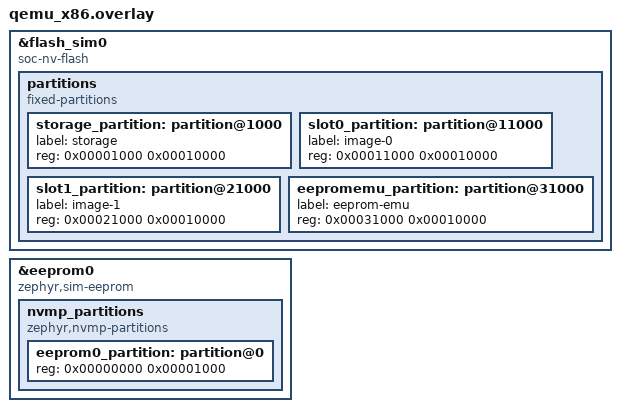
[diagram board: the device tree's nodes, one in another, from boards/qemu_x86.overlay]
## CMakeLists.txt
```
# Copyright (c) 2024 Laczen
# SPDX-License-Identifier: Apache-2.0

cmake_minimum_required(VERSION 3.20.0)

find_package(Zephyr REQUIRED HINTS $ENV{ZEPHYR_BASE})
project(nvmp_test)

target_sources(app PRIVATE src/main.c)
```

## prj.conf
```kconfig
# Copyright (c) 2024 Laczen
# SPDX-License-Identifier: Apache-2.0
CONFIG_NVMP=y
CONFIG_FLASH=y
CONFIG_EEPROM=y
CONFIG_USERSPACE=n
CONFIG_ZTEST=y
```

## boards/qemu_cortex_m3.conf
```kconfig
# Copyright (c) 2023 Laczen
# SPDX-License-Identifier: Apache-2.0
CONFIG_RETAINED_MEM=y
CONFIG_LOG=y
```

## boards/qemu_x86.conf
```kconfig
# Copyright (c) 2023 Laczen
# SPDX-License-Identifier: Apache-2.0
CONFIG_FLASH=y
CONFIG_NVMP_FLASH=y
CONFIG_EEPROM=y
CONFIG_NVMP_EEPROM=y
CONFIG_USERSPACE=n
```

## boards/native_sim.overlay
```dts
/*
 * Copyright (c) 2024 Laczen
 * SPDX-License-Identifier: Apache-2.0
 */

&flash0 {
        compatible = "soc-nv-flash";

	nvmp_partitions {
		compatible = "zephyr,flash-nvmp-fixed-partitions";
		#address-cells = <1>;
		#size-cells = <1>;

		flash0_partition0: partition@0 {
			reg = <0x00000000 0x00002000>;
                        block-size = <DT_SIZE_K(8)>;
		};

                flash0_partition1: partition@2000 {
			reg = <0x00002000 0x00002000>;
			write-block-size = <4>;
		};
	};
};

&eeprom0 {
        compatible = "zephyr,sim-eeprom";

	nvmp_partitions {
		compatible = "zephyr,eeprom-nvmp-fixed-partitions";
		#address-cells = <1>;
		#size-cells = <1>;

		eeprom0_partition0: partition@0 {
			reg = <0x00000000 0x00000800>;
                        block-size = <DT_SIZE_K(1)>;
			status = "okay";
		};

		eeprom0_partition1: partition@800 {
			reg = <0x00000800 0x00000800>;
			status = "okay";
		};

	};
};
```

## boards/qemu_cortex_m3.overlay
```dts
/*
 * Copyright (c) 2023 Laczen
 * SPDX-License-Identifier: Apache-2.0
 */

#include <common/mem.h>

/ {
	sram_2000FC00: sram@2000FC00 {
		compatible = "zephyr,memory-region", "mmio-sram";
		reg = <0x2000FC00 0x400>;
                zephyr,memory-region = "Retention";
                status = "okay";

		retainedmem0: retainedmem {
			compatible = "zephyr,retained-ram", "zephyr,nvmp-retained-mem";
			status = "okay";
			nvmp_partitions {
				compatible = "zephyr,nvmp-partitions";
				#address-cells = <1>;
				#size-cells = <1>;

				retainedmem0_partition: partition@0 {
					reg = <0x00000000 0x0000400>;
				};

			};
	        };
        };
};

&sram0 {
	reg = <0x20000000 0xFC00>;
};
```

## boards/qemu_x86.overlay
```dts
/*
 * Copyright (c) 2023 Laczen
 * SPDX-License-Identifier: Apache-2.0
 */

&flash_sim0 {
        compatible = "soc-nv-flash", "zephyr,nvmp-flash";

	partitions {
		compatible = "fixed-partitions", "zephyr,nvmp-partitions";
		#address-cells = <1>;
		#size-cells = <1>;

		/*
		 * Storage partition will be used by FCB/LittleFS/NVS
		 * if enabled.
		 */
		storage_partition: partition@1000 {
			label = "storage";
			reg = <0x00001000 0x00010000>;
		};

		slot0_partition: partition@11000 {
			label = "image-0";
			reg = <0x00011000 0x00010000>;
		};
		slot1_partition: partition@21000 {
			label = "image-1";
			reg = <0x00021000 0x00010000>;
		};
		eepromemu_partition: partition@31000 {
			label = "eeprom-emu";
			reg = <0x00031000 0x00010000>;
		};
	};
};

&eeprom0 {
        compatible = "zephyr,sim-eeprom", "zephyr,nvmp-eeprom";
        status = "okay";
	nvmp_partitions {
		compatible = "zephyr,nvmp-partitions";
		#address-cells = <1>;
		#size-cells = <1>;

		eeprom0_partition: partition@0 {
			reg = <0x00000000 0x00001000>;
			status = "okay";
		};

	};
};
```

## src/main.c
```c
/*
 * Copyright (c) 2012-2014 Wind River Systems, Inc.
 * SPDX-License-Identifier: Apache-2.0
 */

#include <string.h>
#include <zephyr/kernel.h>
#include <zephyr/ztest.h>
#include <zephyr/storage/nvmp.h>

#define NVMP_FLASH_PARTITION_NODE0  flash0_partition0
#define NVMP_FLASH_PARTITION_NODE1  flash0_partition1
#define NVMP_EEPROM_PARTITION_NODE0 eeprom0_partition0
#define NVMP_EEPROM_PARTITION_NODE1 eeprom0_partition1

ZTEST_BMEM static const struct nvmp_info *nvmp;

static void *nvmp_api_setup(void)
{
	return NULL;
}

ZTEST_USER(nvmp_api, test_read_write_erase)
{
	uint8_t *wr = "/a9/9a/a9/9a";
	uint8_t rd[sizeof(wr)];
	int rc = 0;

	memset(rd, 0, sizeof(rd));

	rc = nvmp_open(nvmp);
	zassert_equal(rc, 0, "open returned [%d]", rc);

	TC_PRINT("nvmp props: size %d, block-size %d, write-block-size %d\n",
		 nvmp->size, nvmp->block_size, nvmp->write_block_size);

	rc = nvmp_read(nvmp, 0, rd, sizeof(rd));
	zassert_equal(rc, 0, "read returned [%d]", rc);

	rc = nvmp_write(nvmp, 0, wr, sizeof(wr));
	zassert_equal(rc, 0, "write returned [%d]", rc);

	rc = nvmp_read(nvmp, 0, rd, sizeof(rd));
	zassert_equal(rc, 0, "read returned [%d]", rc);

	zassert_equal(memcmp(wr, rd, sizeof(rd)), 0, "read/write data differ");

	if (nvmp->erase != NULL) {
		rc = nvmp_erase(nvmp, 0, nvmp->block_size);
		zassert_equal(rc, 0, "erase returned [%d]", rc);
	}

	if (nvmp->clear != NULL) {
		rc = nvmp_clear(nvmp, rd, sizeof(rd));
		zassert_equal(rc, 0, "clear returned [%d]", rc);
	}
}

ZTEST_SUITE(nvmp_api, NULL, nvmp_api_setup, NULL, NULL, NULL);

/* Run all of our tests on the given nvmp */
static void run_tests_on_nvmp(const struct nvmp_info *info)
{
	nvmp = info;
	ztest_run_all(NULL, false, 1, 1);
}

void test_main(void)
{
#ifdef CONFIG_NVMP_FLASH
	run_tests_on_nvmp(NVMP_GET(NVMP_FLASH_PARTITION_NODE0));
	run_tests_on_nvmp(NVMP_GET(NVMP_FLASH_PARTITION_NODE1));
#endif

#ifdef CONFIG_NVMP_EEPROM
	run_tests_on_nvmp(NVMP_GET(NVMP_EEPROM_PARTITION_NODE0));
	run_tests_on_nvmp(NVMP_GET(NVMP_EEPROM_PARTITION_NODE1));
#endif
	ztest_verify_all_test_suites_ran();
}
```
